# M251_v1 register map
File version: 1.0
Registers are 32-bit, read-write, reset 0x0 unless marked. A register's access mark holds for its fields unless they carry their own. Offsets are from the block's base; [hi:lo] are bit positions; {n}, {i} and the like mark numbered series.

## CRYPTO — CRYPTO Register Map
Base 0x50080000
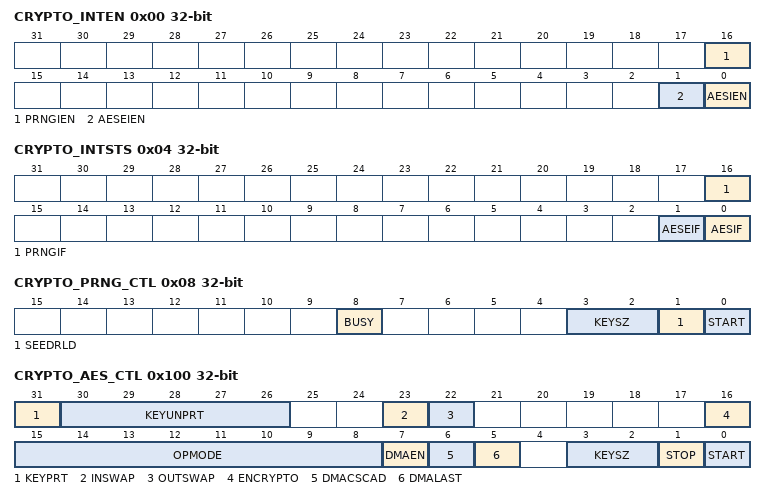
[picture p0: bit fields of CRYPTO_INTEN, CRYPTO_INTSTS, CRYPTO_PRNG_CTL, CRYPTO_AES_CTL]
0x00 CRYPTO_INTEN — Crypto Interrupt Enable Control Register
  [16] PRNGIEN — PRNG Interrupt Enable Bit
    0=PRNG interrupt Disabled; 1=PRNG interrupt Enabled
  [1] AESEIEN — AES Error Flag Enable Bit
    0=AES error interrupt flag Disabled; 1=AES error interrupt flag Enabled
  [0] AESIEN — AES Interrupt Enable Bit. Note: In DMA mode, an interrupt will be triggered when amount of data set in AES_DMA_CNT is fed into the AES engine. In Non-DMA mode, an interrupt will be triggered when the AES engine finishes the operation.
    0=AES interrupt Disabled; 1=AES interrupt Enabled
0x04 CRYPTO_INTSTS — Crypto Interrupt Flag
  [16] PRNGIF — PRNG Finish Interrupt Flag. Note: This bit is cleared by writing 1, and it has no effect by writing 0.
    0=No PRNG interrupt; 1=PRNG key generation done interrupt
  [1] AESEIF — AES Error Flag. Note: This bit is cleared by writing 1, and it has no effect by writing 0.
    0=No AES error; 1=AES encryption/decryption error interrupt
  [0] AESIF — AES Finish Interrupt Flag. Note: This bit is cleared by writing 1, and it has no effect by writing 0.
    0=No AES interrupt; 1=AES encryption/decryption done interrupt
0x08 CRYPTO_PRNG_CTL — PRNG Control Register
  [8] BUSY ro — PRNG Busy (Read Only)
    0=PRNG engine is idle; 1=Indicate that the PRNG engine is generating CRYPTO_PRNG_KEYx
  [3:2] KEYSZ — PRNG Generate Key Size
    0=64 bits; 1=128 bits; 2=192 bits; 3=256 bits
  [1] SEEDRLD — Reload New Seed for PRNG Engine
    0=Generating key based on the current seed; 1=Reload new seed
  [0] START — Start PRNG Engine
    0=Stop PRNG engine; 1=Generate new key and store the new key to register CRYPTO_PRNG_KEYx, which will be cleared when the new key is generated
0x0C CRYPTO_PRNG_SEED wo reset not defined — Seed for PRNG
  [31:0] SEED — Seed for PRNG (Write Only). The bits store the seed for PRNG engine.
{0x10+4i} CRYPTO_PRNG_KEY{i} ro reset not defined (i=0..7) — PRNG Generated Key{i}
  [31:0] KEY — Store PRNG Generated Key (Read Only). The bits store the key that is generated by PRNG.
{0x50+4i} CRYPTO_AES_FDBCK{i} ro (i=0..3) — AES Engine Output Feedback Data After Cryptographic Operation
  [31:0] FDBCK — AES Feedback Information. The feedback value is 128 bits in size. The AES engine uses the data from CRYPTO_AES_FDBCKx as the data inputted to CRYPTO_AES_IVx for the next block in DMA cascade mode. The AES engine outputs feedback information for IV in the next block's operation. Software can store that feedback value temporarily. After switching back, fill the stored feedback value to CRYPTO_AES_IVx in the same channel operation, and then continue the operation with the original setting.
0x100 CRYPTO_AES_CTL — AES Control Register
  [31] KEYPRT — Protect Key. Read as a flag to reflect KEYPRT.
    0=No effect; 1=Protect the content of the AES key from reading. The return value for reading CRYPTO_AES_KEYx is not the content of the registers CRYPTO_AES_KEYx. Once it is set, it can be cleared by asserting KEYUNPRT. And the key content would be cleared as well
  [30:26] KEYUNPRT — Unprotect Key. Writing 0 to CRYPTO_AES_CTL[31] and '10110' to CRYPTO_AES_CTL[30:26] is to unprotect the AES key. The KEYUNPRT can be read and written. When it is written as the AES engine is operating, BUSY flag is 1, there would be no effect on KEYUNPRT.
  [23] INSWAP — AES Engine Input Data Swap
    0=Keep the original order; 1=The order that CPU feeds data to the accelerator will be changed from {byte3, byte2, byte1, byte0} to {byte0, byte1, byte2, byte3}
  [22] OUTSWAP — AES Engine Output Data Swap
    0=Keep the original order; 1=The order that CPU outputs data from the accelerator will be changed from {byte3, byte2, byte1, byte0} to {byte0, byte1, byte2, byte3}
  [16] ENCRYPTO — AES Encryption/Decryption
    0=AES engine executes decryption operation; 1=AES engine executes encryption operation
  [15:8] OPMODE — AES Engine Operation Modes
    0=ECB (Electronic Codebook Mode) 0x01 = CBC (Cipher Block Chaining Mode); 2=CFB (Cipher Feedback Mode); 3=OFB (Output Feedback Mode); 4=CTR (Counter Mode); 16=CBC-CS1 (CBC Ciphertext-Stealing 1 Mode); 17=CBC-CS2 (CBC Ciphertext-Stealing 2 Mode); 18=CBC-CS3 (CBC Ciphertext-Stealing 3 Mode)
  [7] DMAEN — AES Engine DMA Enable Bit. The AES engine operates in DMA mode, and data movement from/to the engine is done by DMA logic.
    0=AES DMA engine Disabled; 1=AES_DMA engine Enabled
  [6] DMACSCAD — AES Engine DMA with Cascade Mode
    0=DMA cascade function Disabled; 1=In DMA cascade mode, software can update DMA source address register, destination address register, and byte count register during a cascade operation, without finishing the accelerator operation
  [5] DMALAST — AES Last Block. In DMA mode, this bit must be set as beginning the last DMA cascade round. In Non-DMA mode, this bit must be set when feeding in the last block of data in ECB, CBC, CTR, OFB, and CFB mode, and feeding in the (last-1) block of data at CBC-CS1, CBC-CS2, and CBC-CS3 mode. This bit is always 0 when it's read back. Must be written again once START is triggered.
  [3:2] KEYSZ — AES Key Size. This bit defines three different key size for AES operation. If the AES accelerator is operating and the corresponding flag BUSY is 1, updating this register has no effect.
  [1] STOP — AES Engine Stop. Note: This bit is always 0 when it's read back.
    0=No effect; 1=Stop AES engine
  [0] START — AES Engine Start. Note: This bit is always 0 when it's read back.
    0=No effect; 1=Start AES engine. BUSY flag will be set
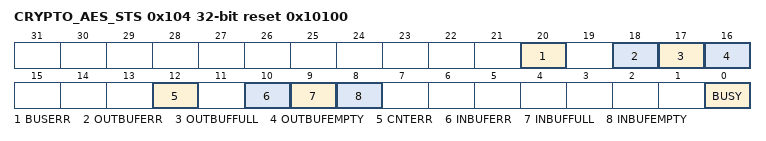
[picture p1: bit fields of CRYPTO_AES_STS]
0x104 CRYPTO_AES_STS ro reset 0x10100 — AES Engine Flag
  [20] BUSERR — AES DMA Access Bus Error Flag
    0=No error; 1=Bus error will stop DMA operation and AES engine
  [18] OUTBUFERR — AES Out Buffer Error Flag
    0=No error; 1=Error happens during getting the result from AES engine
  [17] OUTBUFFULL — AES Out Buffer Full Flag
    0=AES output buffer is not full; 1=AES output buffer is full, and software needs to get data from CRYPTO_AES_DATOUT. Otherwise, the AES engine will be pending since the output buffer is full
  [16] OUTBUFEMPTY — AES Out Buffer Empty
    0=AES output buffer is not empty. There are some valid data kept in output buffer; 1=AES output buffer is empty. Software cannot get data from CRYPTO_AES_DATOUT. Otherwise, the flag OUTBUFERR will be set to 1 since the output buffer is empty
  [12] CNTERR — CRYPTO_ AES_CNT Setting Error
    0=No error in CRYPTO_AES_CNT setting; 1=CRYPTO_AES_CNT is 0 if DMAEN (CRYPTO_AES_CTL[7]) is enabled
  [10] INBUFERR — AES Input Buffer Error Flag
    0=No error; 1=Error happens during feeding data to the AES engine
  [9] INBUFFULL — AES Input Buffer Full Flag
    0=AES input buffer is not full. Software can feed the data into the AES engine; 1=AES input buffer is full. Software cannot feed data to the AES engine. Otherwise, the flag INBUFERR will be set to 1
  [8] INBUFEMPTY — AES Input Buffer Empty
    0=There are some data in input buffer waiting for the AES engine to process; 1=AES input buffer is empty. Software needs to feed data to the AES engine. Otherwise, the AES engine will be pending to wait for input data
  [0] BUSY — AES Engine Busy
    0=The AES engine is idle or finished; 1=The AES engine is under processing
0x108 CRYPTO_AES_DATIN — AES Engine Data Input Port Register
  [31:0] DATIN — AES Engine Input Port. CPU feeds data to AES engine through this port by checking CRYPTO_AES_STS. Feed data as INBUFFULL is 0.
0x10C CRYPTO_AES_DATOUT ro — AES Engine Data Output Port Register
  [31:0] DATOUT — AES Engine Output Port. CPU gets results from the AES engine through this port by checking CRYPTO_AES_STS. Get data as OUTBUFEMPTY is 0.
{0x110+4i} CRYPTO_AES_KEY{i} (i=0..7) — AES Key Word {i} Register
  [31:0] KEY — CRYPTO_AESn_KEYx. The KEY keeps the security key for AES operation. {CRYPTO_AES_KEY3, CRYPTO_AES_KEY2, CRYPTO_AES_KEY1, CRYPTO_AES_KEY0} stores the 128-bit security key for AES operation. {CRYPTO_AES_KEY5, CRYPTO_AES_KEY4, CRYPTO_AES_KEY3, CRYPTO_AES_KEY2, CRYPTO_AES_KEY1, CRYPTO_AES_KEY0} stores the 192-bit security key for AES operation. {CRYPTO_AES_KEY7, CRYPTO_AES_KEY6, CRYPTO_AES_KEY5, CRYPTO_AES_KEY4, CRYPTO_AES_KEY3, CRYPTO_AES_KEY2, CRYPTO_AES_KEY1, CRYPTO_AES_KEY0} stores the 256-bit security key for AES operation.
{0x130+4i} CRYPTO_AES_IV{i} (i=0..3) — AES Initial Vector Word {i} Register
  [31:0] IV — AES Initial Vectors. Four initial vectors (CRYPTO_AES_IV0, CRYPTO_AES_IV1, CRYPTO_AES_IV2, and CRYPTO_AES_IV3) are for AES operating in CBC, CFB, and OFB mode. Four registers (CRYPTO_AES_IV0, CRYPTO_AES_IV1, CRYPTO_AES_IV2, and CRYPTO_AES_IV3) act as Nonce counter when the AES engine is operating in CTR mode.
0x140 CRYPTO_AES_SADDR — AES DMA Source Address Register
  [31:0] SADDR — AES DMA Source Address. The AES accelerator supports DMA function to transfer the plain text between SRAM memory space and embedded FIFO. The SADDR keeps the source address of the data buffer where the source text is stored. Based on the source address, the AES accelerator can read the plain text (encryption) / cipher text (descryption) from SRAM memory space and do AES operation. The start of source address should be located at word boundary. In other words, bit 1 and 0 of SADDR are ignored. SADDR can be read and written. Writing to SADDR while the AES accelerator is operating doesn't affect the current AES operation. But the value of SADDR will be updated later on. Consequently, software can prepare the DMA source address for the next AES operation. In DMA mode, software can update the next CRYPTO_AES_SADDR before triggering START. The value of CRYPTO_AES_SADDR and CRYPTO_AES_DADDR can be the same.
0x144 CRYPTO_AES_DADDR — AES DMA Destination Address Register
  [31:0] DADDR — AES DMA Destination Address. The AES accelerator supports DMA function to transfer the cipher text between SRAM memory space and embedded FIFO. The DADDR keeps the destination address of the data buffer where the engine output's text will be stored. Based on the destination address, the AES accelerator can write the cipher text (encryption) / plain text (decryption) back to SRAM memory space after the AES operation is finished. The start of destination address should be located at word boundary. In other words, bit 1 and 0 of DADDR are ignored. DADDR can be read and written. Writing to DADDR while the AES accelerator is operating doesn't affect the current AES operation. But the value of DADDR will be updated later on. Consequently, software can prepare the destination address for the next AES operation. In DMA mode, software can update the next CRYPTO_AES_DADDR before triggering START. The value of CRYPTO_AES_SADDR and CRYPTO_AES_DADDR can be the same.
0x148 CRYPTO_AES_CNT — AES Byte Count Register
  [31:0] CNT — AES Byte Count. The CRYPTO_AES_CNT keeps the byte count of source text that is for the AES engine operating in DMA mode. The CRYPTO_AES_CNT is 32-bit and the maximum of byte count is 4G bytes. CRYPTO_AESn_CNT can be read and written. Writing to CRYPTO_AES_CNT while the AES accelerator is operating doesn't affect the current AES operation. But the value of CRYPTO_AESn_CNT will be updated later on. Consequently, software can prepare the byte count of data for the next AES operation. According to CBC-CS1, CBC-CS2, and CBC-CS3 standard, the count of operation data must be more than 16 bytes. Operations that are qual or less than one block will output unexpected result. In Non-DMA ECB, CBC, CFB, OFB, and CTR mode, CRYPTO_AES_CNT must be set as byte count for the last block of data before feeding in the last block of data. In Non-DMA CBC-CS1, CBC-CS2, and CBC-CS3 mode, CRYPTO_AES_CNT must be set as byte count for the last two blocks of data before feeding in the last two blocks of data.
